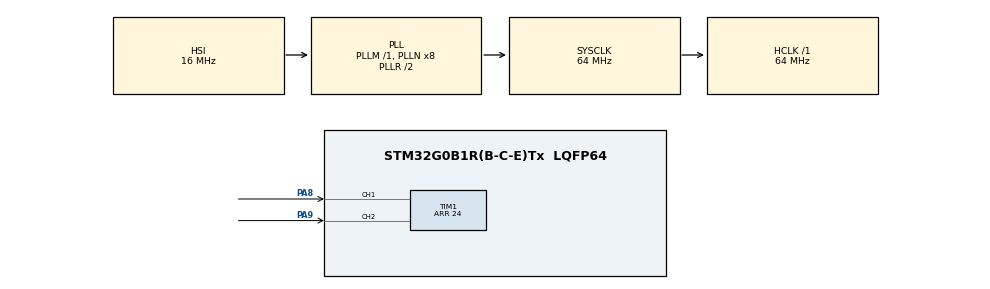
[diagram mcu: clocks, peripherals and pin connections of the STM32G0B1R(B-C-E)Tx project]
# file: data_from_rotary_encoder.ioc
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Mcu.Family=STM32G0
Mcu.Name=STM32G0B1R(B-C-E)Tx
Mcu.Package=LQFP64
PA13.Mode=Serial_Wire
PA13.Signal=SYS_SWDIO
PA14-BOOT0.Mode=Serial_Wire
PA14-BOOT0.Signal=SYS_SWCLK
PA8.GPIO_PuPd=GPIO_PULLUP
PA8.Signal=S_TIM1_CH1
PA9.GPIO_PuPd=GPIO_PULLUP
PA9.Signal=S_TIM1_CH2
PF0-OSC_IN\ (PF0).Mode=HSE-External-Oscillator
PF0-OSC_IN\ (PF0).Signal=RCC_OSC_IN
PF1-OSC_OUT\ (PF1).Mode=HSE-External-Oscillator
PF1-OSC_OUT\ (PF1).Signal=RCC_OSC_OUT
ProjectManager.HeapSize=0x200
ProjectManager.StackSize=0x400
ProjectManager.TargetToolchain=STM32CubeIDE
RCC.ADCFreq_Value=64000000
RCC.AHBFreq_Value=64000000
RCC.CortexFreq_Value=64000000
RCC.EXTERNAL_CLOCK_VALUE=48000
RCC.HCLKFreq_Value=64000000
RCC.HSE_VALUE=8000000
RCC.HSI48_VALUE=48000000
RCC.HSI_VALUE=16000000
RCC.LSE_VALUE=32768
RCC.SYSCLKFreq_VALUE=64000000
RCC.SYSCLKSource=RCC_SYSCLKSOURCE_PLLCLK
RCC.USBFreq_Value=48000000
RCC.VCOOutputFreq_Value=128000000
SH.S_TIM1_CH1.0=TIM1_CH1,Encoder_Interface
SH.S_TIM1_CH2.0=TIM1_CH2,Encoder_Interface
TIM1.EncoderMode=TIM_ENCODERMODE_TI12
TIM1.IC1Filter=10
TIM1.IC2Filter=10
TIM1.Period=24
VP_SYS_VS_DBSignals.Mode=DisableDeadBatterySignals
board=custom

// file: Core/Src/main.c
/* USER CODE BEGIN Header */
/**
  ******************************************************************************
  * @file           : main.c
  * @brief          : Main program body
  ******************************************************************************
  * @attention
  *
  * Copyright (c) 2022 STMicroelectronics.
  * All rights reserved.
  *
  * This software is licensed under terms that can be found in the LICENSE file
  * in the root directory of this software component.
  * If no LICENSE file comes with this software, it is provided AS-IS.
  *
  ******************************************************************************
  */
/* USER CODE END Header */
#include "main.h"

TIM_HandleTypeDef htim1;

void SystemClock_Config(void);
static void MX_GPIO_Init(void);
static void MX_TIM1_Init(void);

/* USER CODE BEGIN 0 */
uint16_t step=0;
/* USER CODE END 0 */

int main(void)
{

  /* MCU Configuration--------------------------------------------------------*/

  /* Reset of all peripherals, Initializes the Flash interface and the Systick. */
  HAL_Init();

  /* Configure the system clock */
  SystemClock_Config();

  /* Initialize all configured peripherals */
  MX_GPIO_Init();
  MX_TIM1_Init();
  /* USER CODE BEGIN 2 */
  HAL_TIM_Encoder_Start(&htim1,TIM_CHANNEL_ALL);
  /* USER CODE END 2 */

  /* Infinite loop */
  while (1)
  {

    /* USER CODE BEGIN 3 */
	  step= __HAL_TIM_GET_COUNTER(&htim1);
	  HAL_Delay(100);
  }
  /* USER CODE END 3 */
}

void SystemClock_Config(void)
{
  RCC_OscInitTypeDef RCC_OscInitStruct = {0};
  RCC_ClkInitTypeDef RCC_ClkInitStruct = {0};

  /** Configure the main internal regulator output voltage
  */
  HAL_PWREx_ControlVoltageScaling(PWR_REGULATOR_VOLTAGE_SCALE1);
  /** Initializes the RCC Oscillators according to the specified parameters
  * in the RCC_OscInitTypeDef structure.
  */
  RCC_OscInitStruct.OscillatorType = RCC_OSCILLATORTYPE_HSI;
  RCC_OscInitStruct.HSIState = RCC_HSI_ON;
  RCC_OscInitStruct.HSIDiv = RCC_HSI_DIV1;
  RCC_OscInitStruct.HSICalibrationValue = RCC_HSICALIBRATION_DEFAULT;
  RCC_OscInitStruct.PLL.PLLState = RCC_PLL_ON;
  RCC_OscInitStruct.PLL.PLLSource = RCC_PLLSOURCE_HSI;
  RCC_OscInitStruct.PLL.PLLM = RCC_PLLM_DIV1;
  RCC_OscInitStruct.PLL.PLLN = 8;
  RCC_OscInitStruct.PLL.PLLP = RCC_PLLP_DIV2;
  RCC_OscInitStruct.PLL.PLLQ = RCC_PLLQ_DIV2;
  RCC_OscInitStruct.PLL.PLLR = RCC_PLLR_DIV2;
  if (HAL_RCC_OscConfig(&RCC_OscInitStruct) != HAL_OK)
  {
    Error_Handler();
  }
  /** Initializes the CPU, AHB and APB buses clocks
  */
  RCC_ClkInitStruct.ClockType = RCC_CLOCKTYPE_HCLK|RCC_CLOCKTYPE_SYSCLK
                              |RCC_CLOCKTYPE_PCLK1;
  RCC_ClkInitStruct.SYSCLKSource = RCC_SYSCLKSOURCE_PLLCLK;
  RCC_ClkInitStruct.AHBCLKDivider = RCC_SYSCLK_DIV1;
  RCC_ClkInitStruct.APB1CLKDivider = RCC_HCLK_DIV1;

  if (HAL_RCC_ClockConfig(&RCC_ClkInitStruct, FLASH_LATENCY_2) != HAL_OK)
  {
    Error_Handler();
  }
}

static void MX_TIM1_Init(void)
{

  TIM_Encoder_InitTypeDef sConfig = {0};
  TIM_MasterConfigTypeDef sMasterConfig = {0};

  htim1.Instance = TIM1;
  htim1.Init.Prescaler = 0;
  htim1.Init.CounterMode = TIM_COUNTERMODE_UP;
  htim1.Init.Period = 24;
  htim1.Init.ClockDivision = TIM_CLOCKDIVISION_DIV1;
  htim1.Init.RepetitionCounter = 0;
  htim1.Init.AutoReloadPreload = TIM_AUTORELOAD_PRELOAD_DISABLE;
  sConfig.EncoderMode = TIM_ENCODERMODE_TI12;
  sConfig.IC1Polarity = TIM_ICPOLARITY_RISING;
  sConfig.IC1Selection = TIM_ICSELECTION_DIRECTTI;
  sConfig.IC1Prescaler = TIM_ICPSC_DIV1;
  sConfig.IC1Filter = 10;
  sConfig.IC2Polarity = TIM_ICPOLARITY_RISING;
  sConfig.IC2Selection = TIM_ICSELECTION_DIRECTTI;
  sConfig.IC2Prescaler = TIM_ICPSC_DIV1;
  sConfig.IC2Filter = 10;
  if (HAL_TIM_Encoder_Init(&htim1, &sConfig) != HAL_OK)
  {
    Error_Handler();
  }
  sMasterConfig.MasterOutputTrigger = TIM_TRGO_RESET;
  sMasterConfig.MasterOutputTrigger2 = TIM_TRGO2_RESET;
  sMasterConfig.MasterSlaveMode = TIM_MASTERSLAVEMODE_DISABLE;
  if (HAL_TIMEx_MasterConfigSynchronization(&htim1, &sMasterConfig) != HAL_OK)
  {
    Error_Handler();
  }

}

static void MX_GPIO_Init(void)
{

  /* GPIO Ports Clock Enable */
  __HAL_RCC_GPIOF_CLK_ENABLE();
  __HAL_RCC_GPIOA_CLK_ENABLE();

}

void Error_Handler(void)
{
  __disable_irq();
  while (1)
  {
  }
}
